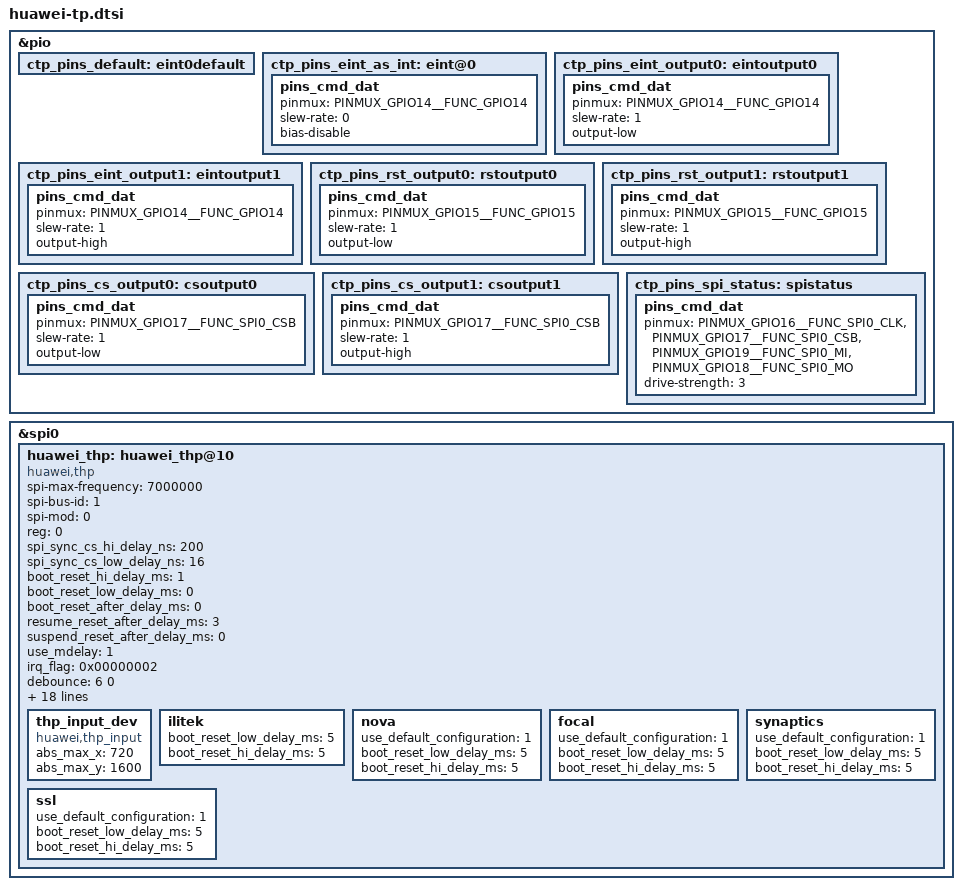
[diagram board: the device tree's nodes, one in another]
&pio {
	ctp_pins_default: eint0default {
	};
	ctp_pins_eint_as_int: eint@0 {
		pins_cmd_dat {
			pinmux = <PINMUX_GPIO14__FUNC_GPIO14>;
			slew-rate = <0>;
			bias-disable;
		};
	};
	ctp_pins_eint_output0: eintoutput0 {
		pins_cmd_dat {
			pinmux = <PINMUX_GPIO14__FUNC_GPIO14>;
			slew-rate = <1>;
			output-low;
		};
	};
	ctp_pins_eint_output1: eintoutput1 {
		pins_cmd_dat {
			pinmux = <PINMUX_GPIO14__FUNC_GPIO14>;
			slew-rate = <1>;
			output-high;
		};
	};
	ctp_pins_rst_output0: rstoutput0 {
		pins_cmd_dat {
			pinmux = <PINMUX_GPIO15__FUNC_GPIO15>;
			slew-rate = <1>;
			output-low;
		};
	};
	ctp_pins_rst_output1: rstoutput1 {
		pins_cmd_dat {
			pinmux = <PINMUX_GPIO15__FUNC_GPIO15>;
			slew-rate = <1>;
			output-high;
		};
	};

	ctp_pins_cs_output0: csoutput0 {
		pins_cmd_dat {
			pinmux = <PINMUX_GPIO17__FUNC_SPI0_CSB>;
			slew-rate = <1>;
			output-low;
		};
	};
	ctp_pins_cs_output1: csoutput1 {
		pins_cmd_dat {
			pinmux = <PINMUX_GPIO17__FUNC_SPI0_CSB>;
			slew-rate = <1>;
			output-high;
		};
	};
	ctp_pins_spi_status: spistatus   {
		pins_cmd_dat {
			pinmux = <PINMUX_GPIO16__FUNC_SPI0_CLK>,
				 <PINMUX_GPIO17__FUNC_SPI0_CSB>,
				 <PINMUX_GPIO19__FUNC_SPI0_MI>,
				 <PINMUX_GPIO18__FUNC_SPI0_MO>;
			drive-strength = <3>;
		};
	};
};

&spi0 {
    status = "ok";
    huawei_thp: huawei_thp@10 {
        compatible = "huawei,thp";
        /* SPI Config */
        spi-max-frequency = <7000000>;
        spi-bus-id = <1>;
        spi-mod = <0>;
        reg = <0>;
        spi_sync_cs_hi_delay_ns  = <200>;
        spi_sync_cs_low_delay_ns = <16>;
        /* Power Config */
        boot_reset_hi_delay_ms = <1>;
        boot_reset_low_delay_ms = <0>;
        boot_reset_after_delay_ms = <0>;
        resume_reset_after_delay_ms = <3>;
        suspend_reset_after_delay_ms = <0>;
        use_mdelay = <1>;
        /* GPIO Config */
        irq_flag = <0x00000002>;
        debounce = <6 0>;
        interrupt-parent = <&pio>;
        interrupts = <14 2 0 0>;
        /* PinCtrl Config */
        support_pinctrl = <1>;
        pinctrl-names = "default", "idle", "state_eint_as_int", "state_rst_output0",
            "state_rst_output1", "state_cs_output0", "state_cs_output1", "state_spi_status";
        pinctrl-0 = <&ctp_pins_rst_output1 &ctp_pins_cs_output1>;
        pinctrl-1 = <&ctp_pins_rst_output0 &ctp_pins_cs_output0>;
        pinctrl-2 = <&ctp_pins_eint_as_int>;
        pinctrl-3 = <&ctp_pins_rst_output0>;
        pinctrl-4 = <&ctp_pins_rst_output1>;
        pinctrl-5 = <&ctp_pins_cs_output0>;
        pinctrl-6 = <&ctp_pins_cs_output1>;
        pinctrl-7 = <&ctp_pins_spi_status>;

        /* Feature Config */
        pt_station_test = <1>;
        proximity_support = <0>;
        hide_product_info_en = <1>;
        change_spi_driving_force = <1>;
        support_no_cs_pinctrl_for_mtk = <1>;
        /* Input Config */
        thp_input_dev {
            compatible = "huawei,thp_input";
            abs_max_x = <720>;
            abs_max_y = <1600>;
        };
        ilitek {
            boot_reset_low_delay_ms = <5>;
            boot_reset_hi_delay_ms = <5>;
        };
        nova {
            use_default_configuration = <1>;
            boot_reset_low_delay_ms = <5>;
            boot_reset_hi_delay_ms = <5>;
        };
        focal {
            use_default_configuration = <1>;
            boot_reset_low_delay_ms = <5>;
            boot_reset_hi_delay_ms = <5>;
        };
        synaptics {
            use_default_configuration = <1>;
            boot_reset_low_delay_ms = <5>;
            boot_reset_hi_delay_ms = <5>;
        };
        ssl {
            use_default_configuration = <1>;
            boot_reset_low_delay_ms = <5>;
            boot_reset_hi_delay_ms = <5>;
        };
    };
};
